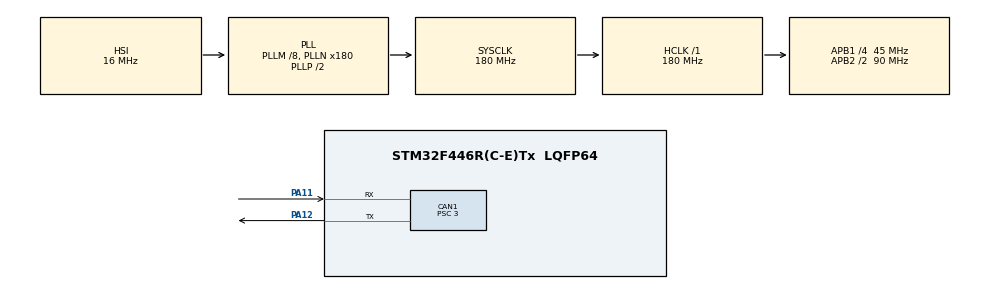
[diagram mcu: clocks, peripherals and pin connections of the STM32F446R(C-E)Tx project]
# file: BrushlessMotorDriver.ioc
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CAN1.ABOM=ENABLE
CAN1.BS1=CAN_BS1_12TQ
CAN1.BS2=CAN_BS2_2TQ
CAN1.CalculateBaudRate=1000000
CAN1.CalculateTimeBit=1000
CAN1.CalculateTimeQuantum=66.66666666666666
CAN1.NART=ENABLE
CAN1.Prescaler=3
Mcu.Family=STM32F4
Mcu.Name=STM32F446R(C-E)Tx
Mcu.Package=LQFP64
NVIC.PriorityGroup=NVIC_PRIORITYGROUP_4
PA11.Mode=CAN_Activate
PA11.Signal=CAN1_RX
PA12.Mode=CAN_Activate
PA12.Signal=CAN1_TX
PA13.Mode=Serial_Wire
PA13.Signal=SYS_JTMS-SWDIO
PA14.Mode=Serial_Wire
PA14.Signal=SYS_JTCK-SWCLK
ProjectManager.HeapSize=0x200
ProjectManager.StackSize=0x400
ProjectManager.TargetToolchain=STM32CubeIDE
RCC.AHBFreq_Value=180000000
RCC.APB1CLKDivider=RCC_HCLK_DIV4
RCC.APB1Freq_Value=45000000
RCC.APB1TimFreq_Value=90000000
RCC.APB2CLKDivider=RCC_HCLK_DIV2
RCC.APB2Freq_Value=90000000
RCC.APB2TimFreq_Value=180000000
RCC.CortexFreq_Value=180000000
RCC.HCLKFreq_Value=180000000
RCC.PLLM=8
RCC.PLLN=180
RCC.SYSCLKFreq_VALUE=180000000
RCC.SYSCLKSource=RCC_SYSCLKSOURCE_PLLCLK
RCC.USBFreq_Value=180000000
RCC.VCOOutputFreq_Value=360000000
board=custom

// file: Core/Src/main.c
/* USER CODE BEGIN Header */
/**
  ******************************************************************************
  * @file           : main.c
  * @brief          : Main program body
  ******************************************************************************
  * @attention
  *
  * Copyright (c) 2022 STMicroelectronics.
  * All rights reserved.
  *
  * This software is licensed under terms that can be found in the LICENSE file
  * in the root directory of this software component.
  * If no LICENSE file comes with this software, it is provided AS-IS.
  *
  ******************************************************************************
  */
/* USER CODE END Header */
#include "main.h"

/* USER CODE BEGIN Includes */
#include <wrapper.h>
/* USER CODE END Includes */

CAN_HandleTypeDef hcan1;

void SystemClock_Config(void);
static void MX_GPIO_Init(void);
static void MX_CAN1_Init(void);

int main(void)
{

  /* MCU Configuration--------------------------------------------------------*/

  /* Reset of all peripherals, Initializes the Flash interface and the Systick. */
  HAL_Init();

  /* Configure the system clock */
  SystemClock_Config();

  /* Initialize all configured peripherals */
  MX_GPIO_Init();
  MX_CAN1_Init();
  /* USER CODE BEGIN 2 */

  main_cpp(&hcan1, &htim/*x*/);
  /* USER CODE END 2 */

  /* Infinite loop */
  while (1)
  {

  }
}

void SystemClock_Config(void)
{
  RCC_OscInitTypeDef RCC_OscInitStruct = {0};
  RCC_ClkInitTypeDef RCC_ClkInitStruct = {0};

  /** Configure the main internal regulator output voltage
  */
  __HAL_RCC_PWR_CLK_ENABLE();
  __HAL_PWR_VOLTAGESCALING_CONFIG(PWR_REGULATOR_VOLTAGE_SCALE1);

  /** Initializes the RCC Oscillators according to the specified parameters
  * in the RCC_OscInitTypeDef structure.
  */
  RCC_OscInitStruct.OscillatorType = RCC_OSCILLATORTYPE_HSI;
  RCC_OscInitStruct.HSIState = RCC_HSI_ON;
  RCC_OscInitStruct.HSICalibrationValue = RCC_HSICALIBRATION_DEFAULT;
  RCC_OscInitStruct.PLL.PLLState = RCC_PLL_ON;
  RCC_OscInitStruct.PLL.PLLSource = RCC_PLLSOURCE_HSI;
  RCC_OscInitStruct.PLL.PLLM = 8;
  RCC_OscInitStruct.PLL.PLLN = 180;
  RCC_OscInitStruct.PLL.PLLP = RCC_PLLP_DIV2;
  RCC_OscInitStruct.PLL.PLLQ = 2;
  RCC_OscInitStruct.PLL.PLLR = 2;
  if (HAL_RCC_OscConfig(&RCC_OscInitStruct) != HAL_OK)
  {
    Error_Handler();
  }

  /** Activate the Over-Drive mode
  */
  if (HAL_PWREx_EnableOverDrive() != HAL_OK)
  {
    Error_Handler();
  }

  /** Initializes the CPU, AHB and APB buses clocks
  */
  RCC_ClkInitStruct.ClockType = RCC_CLOCKTYPE_HCLK|RCC_CLOCKTYPE_SYSCLK
                              |RCC_CLOCKTYPE_PCLK1|RCC_CLOCKTYPE_PCLK2;
  RCC_ClkInitStruct.SYSCLKSource = RCC_SYSCLKSOURCE_PLLCLK;
  RCC_ClkInitStruct.AHBCLKDivider = RCC_SYSCLK_DIV1;
  RCC_ClkInitStruct.APB1CLKDivider = RCC_HCLK_DIV4;
  RCC_ClkInitStruct.APB2CLKDivider = RCC_HCLK_DIV2;

  if (HAL_RCC_ClockConfig(&RCC_ClkInitStruct, FLASH_LATENCY_5) != HAL_OK)
  {
    Error_Handler();
  }
}

static void MX_CAN1_Init(void)
{

  hcan1.Instance = CAN1;
  hcan1.Init.Prescaler = 3;
  hcan1.Init.Mode = CAN_MODE_NORMAL;
  hcan1.Init.SyncJumpWidth = CAN_SJW_1TQ;
  hcan1.Init.TimeSeg1 = CAN_BS1_12TQ;
  hcan1.Init.TimeSeg2 = CAN_BS2_2TQ;
  hcan1.Init.TimeTriggeredMode = DISABLE;
  hcan1.Init.AutoBusOff = ENABLE;
  hcan1.Init.AutoWakeUp = DISABLE;
  hcan1.Init.AutoRetransmission = ENABLE;
  hcan1.Init.ReceiveFifoLocked = DISABLE;
  hcan1.Init.TransmitFifoPriority = DISABLE;
  if (HAL_CAN_Init(&hcan1) != HAL_OK)
  {
    Error_Handler();
  }

}

static void MX_GPIO_Init(void)
{

  /* GPIO Ports Clock Enable */
  __HAL_RCC_GPIOA_CLK_ENABLE();

}

void Error_Handler(void)
{
  __disable_irq();
  while (1)
  {
  }
}
